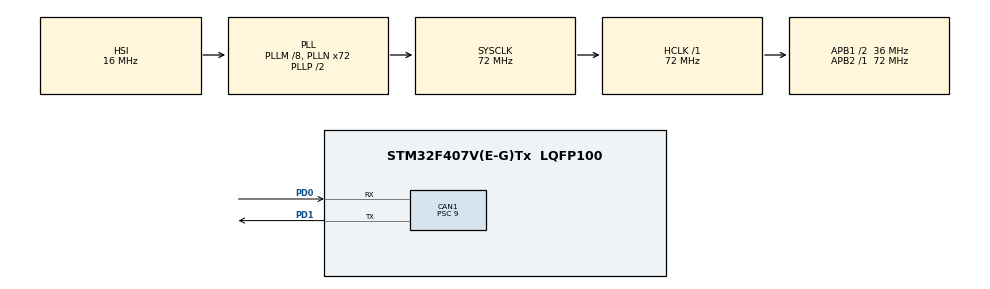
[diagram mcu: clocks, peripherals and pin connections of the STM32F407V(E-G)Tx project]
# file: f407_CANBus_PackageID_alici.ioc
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CAN1.BS1=CAN_BS1_10TQ
CAN1.BS2=CAN_BS2_5TQ
CAN1.CalculateBaudRate=250000
CAN1.CalculateTimeBit=4000
CAN1.CalculateTimeQuantum=250.0
CAN1.Prescaler=9
Mcu.Family=STM32F4
Mcu.Name=STM32F407V(E-G)Tx
Mcu.Package=LQFP100
NVIC.PriorityGroup=NVIC_PRIORITYGROUP_4
PA13.Mode=Serial_Wire
PA13.Signal=SYS_JTMS-SWDIO
PA14.Mode=Serial_Wire
PA14.Signal=SYS_JTCK-SWCLK
PD0.Mode=CAN_Activate
PD0.Signal=CAN1_RX
PD1.Mode=CAN_Activate
PD1.Signal=CAN1_TX
PH0-OSC_IN.Mode=HSE-External-Oscillator
PH0-OSC_IN.Signal=RCC_OSC_IN
PH1-OSC_OUT.Mode=HSE-External-Oscillator
PH1-OSC_OUT.Signal=RCC_OSC_OUT
ProjectManager.HeapSize=0x200
ProjectManager.StackSize=0x400
ProjectManager.TargetToolchain=STM32CubeIDE
RCC.48MHZClocksFreq_Value=36000000
RCC.AHBFreq_Value=72000000
RCC.APB1CLKDivider=RCC_HCLK_DIV2
RCC.APB1Freq_Value=36000000
RCC.APB1TimFreq_Value=72000000
RCC.APB2Freq_Value=72000000
RCC.APB2TimFreq_Value=72000000
RCC.CortexFreq_Value=72000000
RCC.HCLKFreq_Value=72000000
RCC.HSE_VALUE=25000000
RCC.HSI_VALUE=16000000
RCC.LSE_VALUE=32768
RCC.PLLM=8
RCC.PLLN=72
RCC.SYSCLKFreq_VALUE=72000000
RCC.SYSCLKSource=RCC_SYSCLKSOURCE_PLLCLK
RCC.VCOOutputFreq_Value=144000000
board=custom

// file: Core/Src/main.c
/* USER CODE BEGIN Header */
/**
  ******************************************************************************
  * @file           : main.c
  * @brief          : Main program body
  ******************************************************************************
  * @attention
  *
  * Copyright (c) 2024 STMicroelectronics.
  * All rights reserved.
  *
  * This software is licensed under terms that can be found in the LICENSE file
  * in the root directory of this software component.
  * If no LICENSE file comes with this software, it is provided AS-IS.
  *
  ******************************************************************************
  */
/* USER CODE END Header */
#include "main.h"

/* USER CODE BEGIN Includes */
#include<math.h>

/* USER CODE END Includes */

CAN_HandleTypeDef hcan1;

/* USER CODE BEGIN PV */
uint8_t tempPackage1[8];
uint8_t tempPackage1_msb[8];
uint8_t tempPackage1_lsb[8];
float temps[8];
/* USER CODE END PV */

void SystemClock_Config(void);
static void MX_GPIO_Init(void);
static void MX_CAN1_Init(void);

/* USER CODE BEGIN 0 */
CAN_RxHeaderTypeDef RxHeader;

/* USER CODE END 0 */

int main(void)
{

  /* MCU Configuration--------------------------------------------------------*/

  /* Reset of all peripherals, Initializes the Flash interface and the Systick. */
  HAL_Init();

  /* Configure the system clock */
  SystemClock_Config();

  /* Initialize all configured peripherals */
  MX_GPIO_Init();
  MX_CAN1_Init();
  /* USER CODE BEGIN 2 */
  HAL_CAN_Start(&hcan1);

  /* USER CODE END 2 */

  /* Infinite loop */
  while (1)
  {

    /* USER CODE BEGIN 3 */
	  HAL_CAN_GetRxMessage(&hcan1, CAN_RX_FIFO0, &RxHeader, tempPackage1);
	  if(tempPackage1[0] == 254){
		  tempPackage1_msb[1]= tempPackage1[1];
		  tempPackage1_msb[2]= tempPackage1[2];
		  tempPackage1_msb[3]= tempPackage1[3];
		  tempPackage1_msb[4]= tempPackage1[4];
		  tempPackage1_msb[5]= tempPackage1[5];
		  tempPackage1_msb[6]= tempPackage1[6];
		  tempPackage1_msb[7]= tempPackage1[7];
	  }
	  if(tempPackage1[0] == 250){
	  		  tempPackage1_lsb[1]= tempPackage1[1];
	  		  tempPackage1_lsb[2]= tempPackage1[2];
	  		  tempPackage1_lsb[3]= tempPackage1[3];
	  		  tempPackage1_lsb[4]= tempPackage1[4];
	  		  tempPackage1_lsb[5]= tempPackage1[5];
	  		  tempPackage1_lsb[6]= tempPackage1[6];
	  		  tempPackage1_lsb[7]= tempPackage1[7];
	  	  }

	  HAL_Delay(50);
	  for(int i = 1;i<8;i++){
		  int x = (int)tempPackage1_msb[i];
		  int y = (int)tempPackage1_lsb[i];
		  temps[i] = (float)x+(float)(y/100.00);
	  }

  }
  /* USER CODE END 3 */
}

void SystemClock_Config(void)
{
  RCC_OscInitTypeDef RCC_OscInitStruct = {0};
  RCC_ClkInitTypeDef RCC_ClkInitStruct = {0};

  /** Configure the main internal regulator output voltage
  */
  __HAL_RCC_PWR_CLK_ENABLE();
  __HAL_PWR_VOLTAGESCALING_CONFIG(PWR_REGULATOR_VOLTAGE_SCALE1);

  /** Initializes the RCC Oscillators according to the specified parameters
  * in the RCC_OscInitTypeDef structure.
  */
  RCC_OscInitStruct.OscillatorType = RCC_OSCILLATORTYPE_HSI;
  RCC_OscInitStruct.HSIState = RCC_HSI_ON;
  RCC_OscInitStruct.HSICalibrationValue = RCC_HSICALIBRATION_DEFAULT;
  RCC_OscInitStruct.PLL.PLLState = RCC_PLL_ON;
  RCC_OscInitStruct.PLL.PLLSource = RCC_PLLSOURCE_HSI;
  RCC_OscInitStruct.PLL.PLLM = 8;
  RCC_OscInitStruct.PLL.PLLN = 72;
  RCC_OscInitStruct.PLL.PLLP = RCC_PLLP_DIV2;
  RCC_OscInitStruct.PLL.PLLQ = 4;
  if (HAL_RCC_OscConfig(&RCC_OscInitStruct) != HAL_OK)
  {
    Error_Handler();
  }

  /** Initializes the CPU, AHB and APB buses clocks
  */
  RCC_ClkInitStruct.ClockType = RCC_CLOCKTYPE_HCLK|RCC_CLOCKTYPE_SYSCLK
                              |RCC_CLOCKTYPE_PCLK1|RCC_CLOCKTYPE_PCLK2;
  RCC_ClkInitStruct.SYSCLKSource = RCC_SYSCLKSOURCE_PLLCLK;
  RCC_ClkInitStruct.AHBCLKDivider = RCC_SYSCLK_DIV1;
  RCC_ClkInitStruct.APB1CLKDivider = RCC_HCLK_DIV2;
  RCC_ClkInitStruct.APB2CLKDivider = RCC_HCLK_DIV1;

  if (HAL_RCC_ClockConfig(&RCC_ClkInitStruct, FLASH_LATENCY_2) != HAL_OK)
  {
    Error_Handler();
  }
}

static void MX_CAN1_Init(void)
{

  hcan1.Instance = CAN1;
  hcan1.Init.Prescaler = 9;
  hcan1.Init.Mode = CAN_MODE_NORMAL;
  hcan1.Init.SyncJumpWidth = CAN_SJW_1TQ;
  hcan1.Init.TimeSeg1 = CAN_BS1_10TQ;
  hcan1.Init.TimeSeg2 = CAN_BS2_5TQ;
  hcan1.Init.TimeTriggeredMode = DISABLE;
  hcan1.Init.AutoBusOff = DISABLE;
  hcan1.Init.AutoWakeUp = DISABLE;
  hcan1.Init.AutoRetransmission = DISABLE;
  hcan1.Init.ReceiveFifoLocked = DISABLE;
  hcan1.Init.TransmitFifoPriority = DISABLE;
  if (HAL_CAN_Init(&hcan1) != HAL_OK)
  {
    Error_Handler();
  }
  /* USER CODE BEGIN CAN1_Init 2 */
  CAN_FilterTypeDef canfilterconfig;

      canfilterconfig.FilterActivation = CAN_FILTER_ENABLE;
      canfilterconfig.FilterBank = 18;  // which filter bank to use from the assigned ones
      canfilterconfig.FilterFIFOAssignment = CAN_FILTER_FIFO0;
      canfilterconfig.FilterIdHigh = 0x0000<<5;
      canfilterconfig.FilterIdLow = 0;
      canfilterconfig.FilterMaskIdHigh = 0x0000<<5;
      canfilterconfig.FilterMaskIdLow = 0x0000;
      canfilterconfig.FilterMode = CAN_FILTERMODE_IDMASK;
      canfilterconfig.FilterScale = CAN_FILTERSCALE_32BIT;
      canfilterconfig.SlaveStartFilterBank = 20;  // how many filters to assign to the CAN1 (master can)

      HAL_CAN_ConfigFilter(&hcan1, &canfilterconfig);
  /* USER CODE END CAN1_Init 2 */

}

static void MX_GPIO_Init(void)
{

  /* GPIO Ports Clock Enable */
  __HAL_RCC_GPIOH_CLK_ENABLE();
  __HAL_RCC_GPIOA_CLK_ENABLE();
  __HAL_RCC_GPIOD_CLK_ENABLE();

}

void Error_Handler(void)
{
  __disable_irq();
  while (1)
  {
  }
}
